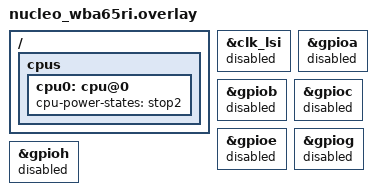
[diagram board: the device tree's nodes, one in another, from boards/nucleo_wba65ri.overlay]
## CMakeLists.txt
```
# SPDX-License-Identifier: Apache-2.0

cmake_minimum_required(VERSION 3.20.0)
find_package(Zephyr REQUIRED HINTS $ENV{ZEPHYR_BASE})
project(blinky_PWR_stop2)

target_sources(app PRIVATE src/main.c)
```

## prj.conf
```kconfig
# Power management
CONFIG_PM=y
CONFIG_PM_DEVICE=y
CONFIG_PM_DEVICE_RUNTIME=y
CONFIG_PM_DEVICE_SYSTEM_MANAGED=y

# GPIO
CONFIG_GPIO=y
CONFIG_PINCTRL=y

# Debug
CONFIG_DEBUG=n

CONFIG_UART_CONSOLE=n
```

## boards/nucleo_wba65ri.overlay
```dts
/*
 * SPDX-License-Identifier: Apache-2.0
 *
 * Copyright (c) 2023 STMicroelectronics
 */

/ {
	cpus {
		cpu0: cpu@0 {
			cpu-power-states = <&stop2>;
		};
	};
};

&clk_lsi {
	status = "disabled";
};


/* disable unused GPIOs */
&gpioa {
    status = "disabled";
};
&gpiob {
    status = "disabled";
};
&gpioc {
    status = "disabled";
};
/* GPIOd used for LED */
// &gpiod {
//     status = "disabled";
// };
&gpioe {
    status = "disabled";
};
&gpiog {
    status = "disabled";
};
&gpioh {
    status = "disabled";
};
```

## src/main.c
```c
/*
 * Copyright (c) 2021 Linaro Limited
 *
 * SPDX-License-Identifier: Apache-2.0
 */

#include <zephyr/kernel.h>
#include <zephyr/device.h>

#include <zephyr/init.h>
#include <zephyr/pm/policy.h>


#define SLEEP_TIME_MS   2000


#if defined(CONFIG_GPIO)
/* The devicetree node identifier for the "led0" alias. */
#define LED0_NODE DT_ALIAS(led0)

#if DT_NODE_HAS_STATUS_OKAY(LED0_NODE)
#include <zephyr/drivers/gpio.h>
#include <stm32wbaxx_ll_gpio.h>
#include <stm32wbaxx_ll_bus.h>
#define HAS_LED     1

static const struct gpio_dt_spec led = GPIO_DT_SPEC_GET(DT_ALIAS(led0), gpios);

// Define portable LL-compatible port/pin from devicetree
#define LED_GPIO_PORT ((GPIO_TypeDef *)DT_REG_ADDR(DT_GPIO_CTLR(DT_ALIAS(led0), gpios)))
#define LED_GPIO_PIN  (1U << DT_GPIO_PIN(DT_ALIAS(led0), gpios))  // Bitmask version

#endif /* LED0_NODE */
#endif /* CONFIG_GPIO */


static int blink_setup(void)
{
#if defined(HAS_LED)
	int err;
	printk("Checking LED device...");
	if (!gpio_is_ready_dt(&led)) {
		printk("failed.\n");
		return -EIO;
	}
	printk("done.\n");

	printk("Configuring GPIO pin...");
	err = gpio_pin_configure_dt(&led, GPIO_OUTPUT_ACTIVE);
	if (err) {
		printk("failed.\n");
		return -EIO;
	}
	printk("done.\n");

#endif
	return 0;
}

static void led_on(void)
{
#if defined(HAS_LED)
	printk("LED on\n");
	gpio_pin_configure_dt(&led, GPIO_OUTPUT_ACTIVE);
#endif
}

static void led_off(void)
{
#if defined(HAS_LED)
	printk("LED off\n");

	LL_AHB2_GRP1_EnableClock(LL_AHB2_GRP1_PERIPH_GPIOD);
    LL_GPIO_SetPinMode(LED_GPIO_PORT, LED_GPIO_PIN, LL_GPIO_MODE_ANALOG);
	LL_AHB2_GRP1_DisableClock(LL_AHB2_GRP1_PERIPH_GPIOD); 
	
#endif
}

int main(void)
{
	int err;

	printk("Device ready\n");

#if defined(HAS_LED)
	err = blink_setup();
	if (err) {
		return 0;
	}

#endif /* HAS_LED */

	while (true) {
		led_on();
		k_msleep(SLEEP_TIME_MS);
		led_off();
		k_msleep(SLEEP_TIME_MS);
		
	}
	return 0;
}
```
